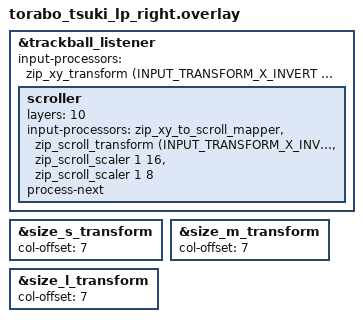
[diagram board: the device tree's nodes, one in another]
#include "torabo_tsuki_lp.dtsi"
#include <input/processors.dtsi>
#include <dt-bindings/zmk/input_transform.h>

&trackball_listener {
    input-processors = 
        <&zip_xy_transform (INPUT_TRANSFORM_X_INVERT | INPUT_TRANSFORM_Y_INVERT)>;

    scroller {
	    layers = <10>; // config/keymap.keymap の SCROLL レイヤー
        // divisor 128 は ZMK 推奨上限 (16) を超えるため、1/16 x 1/8 の2段チェーンに分割
        input-processors = <&zip_xy_to_scroll_mapper>, <&zip_scroll_transform (INPUT_TRANSFORM_X_INVERT)>, <&zip_scroll_scaler 1 16>, <&zip_scroll_scaler 1 8>;
        process-next;
    };
};

&size_s_transform {
    col-offset = <7>;
};

&size_m_transform {
    col-offset = <7>;
};

&size_l_transform {
    col-offset = <7>;
};
